# SMS_LITE_FWMGR_0_CBASS_GLB_45B00800h register map
Vendor: Texas Instruments
Peripheral module from a debugger description file (folder am62L).
Registers are 32-bit, read-only, reset 0x66005902 unless marked. A register's access mark holds for its fields unless they carry their own. Offsets are as the file gives them; lines under a group give offsets from that group; [hi:lo] are bit positions; {n}, {i} and the like mark numbered series; 'fields as' and 'values as' point back to an identical list; <NAME> marks a mode.

## cbass_glb
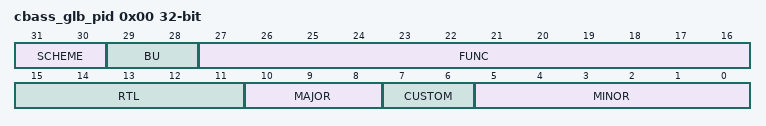
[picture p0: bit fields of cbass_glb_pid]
0x00 cbass_glb_pid — The Revision Register contains the major and minor revisions for the module.
  [31:30] SCHEME — PID register scheme Reset Source: sms_custom_rst_mod_g_rst_n
  [29:28] BU — Business Unit: 10 = Processors Reset Source: sms_custom_rst_mod_g_rst_n
  [27:16] FUNC — Module ID Reset Source: sms_custom_rst_mod_g_rst_n
  [15:11] RTL — RTL revision. Will vary depending on release. Reset Source: sms_custom_rst_mod_g_rst_n
  [10:8] MAJOR — Major revision Reset Source: sms_custom_rst_mod_g_rst_n
  [7:6] CUSTOM — Custom Reset Source: sms_custom_rst_mod_g_rst_n
  [5:0] MINOR — Minor revision Reset Source: sms_custom_rst_mod_g_rst_n
